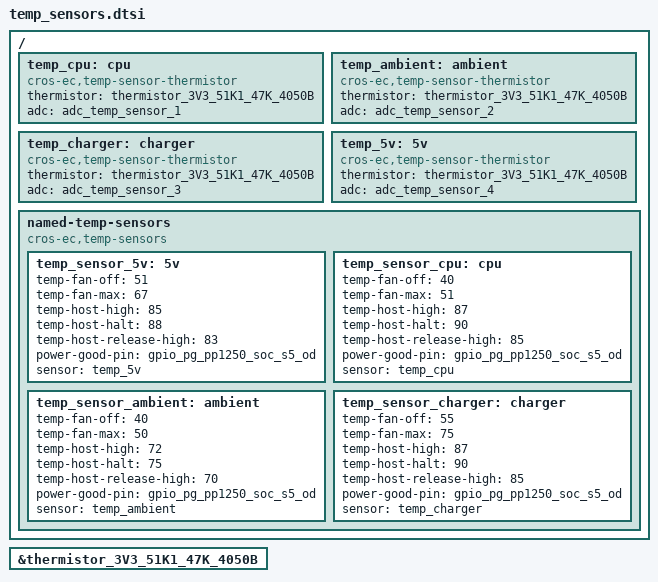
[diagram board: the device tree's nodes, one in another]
/* Copyright 2026 The ChromiumOS Authors
 * Use of this source code is governed by a BSD-style license that can be
 * found in the LICENSE file.
 */

#include <cros/thermistor/thermistor.dtsi>

/ {
	temp_cpu: cpu {
		compatible = "cros-ec,temp-sensor-thermistor";
		thermistor = <&thermistor_3V3_51K1_47K_4050B>;
		adc = <&adc_temp_sensor_1>;
	};
	temp_ambient: ambient {
		compatible = "cros-ec,temp-sensor-thermistor";
		thermistor = <&thermistor_3V3_51K1_47K_4050B>;
		adc = <&adc_temp_sensor_2>;
	};
	temp_charger: charger {
		compatible = "cros-ec,temp-sensor-thermistor";
		thermistor = <&thermistor_3V3_51K1_47K_4050B>;
		adc = <&adc_temp_sensor_3>;
	};
	temp_5v: 5v {
		compatible = "cros-ec,temp-sensor-thermistor";
		thermistor = <&thermistor_3V3_51K1_47K_4050B>;
		adc = <&adc_temp_sensor_4>;
	};

	named-temp-sensors {
		compatible = "cros-ec,temp-sensors";

		temp_sensor_5v: 5v {
			temp-fan-off = <51>;
			temp-fan-max = <67>;
			temp-host-high = <85>;
			temp-host-halt = <88>;
			temp-host-release-high = <83>;
			power-good-pin = <&gpio_pg_pp1250_soc_s5_od>;
			sensor = <&temp_5v>;
		};
		temp_sensor_cpu: cpu {
			temp-fan-off = <40>;
			temp-fan-max = <51>;
			temp-host-high = <87>;
			temp-host-halt = <90>;
			temp-host-release-high = <85>;
			power-good-pin = <&gpio_pg_pp1250_soc_s5_od>;
			sensor = <&temp_cpu>;
		};
		temp_sensor_ambient: ambient {
			temp-fan-off = <40>;
			temp-fan-max = <50>;
			temp-host-high = <72>;
			temp-host-halt = <75>;
			temp-host-release-high = <70>;
			power-good-pin = <&gpio_pg_pp1250_soc_s5_od>;
			sensor = <&temp_ambient>;
		};
		temp_sensor_charger: charger {
			temp-fan-off = <55>;
			temp-fan-max = <75>;
			temp-host-high = <87>;
			temp-host-halt = <90>;
			temp-host-release-high = <85>;
			power-good-pin = <&gpio_pg_pp1250_soc_s5_od>;
			sensor = <&temp_charger>;
		};
	};
};

&thermistor_3V3_51K1_47K_4050B {
	status = "okay";
};
